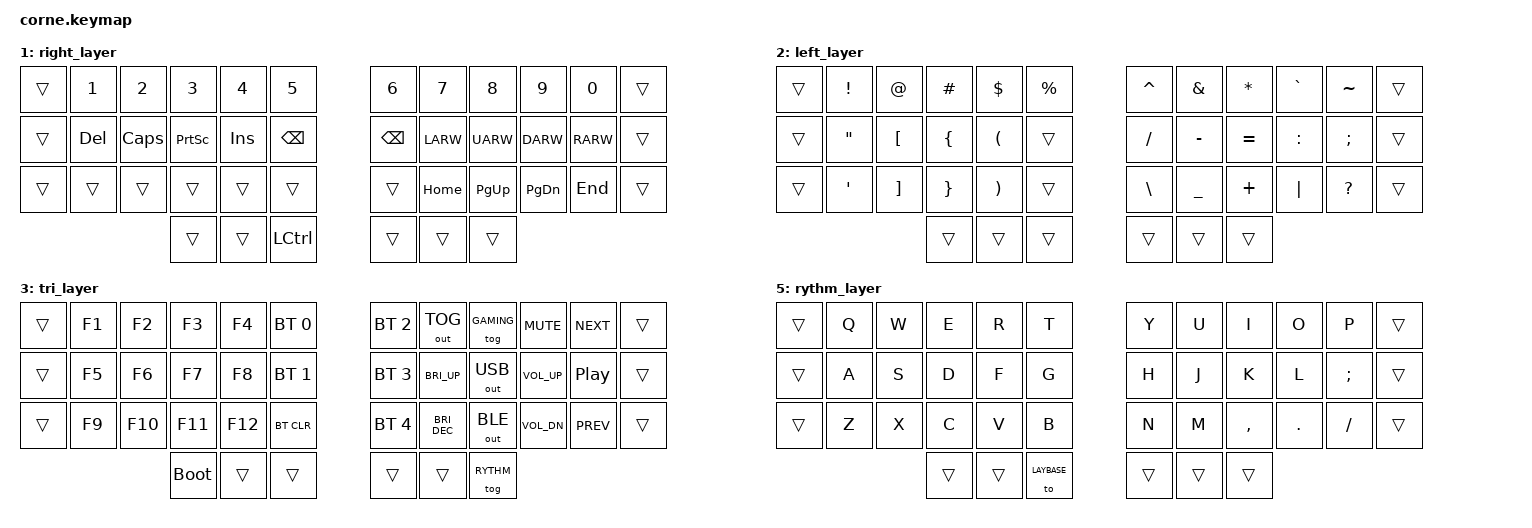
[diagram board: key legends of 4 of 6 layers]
// Copyright (c) 2022 The ZMK Contributors
// SPDX-License-Identifier: MIT
// This should be used with US International keyboard layout for those who need diacritics or Ñ

#include <behaviors.dtsi>
#include <dt-bindings/zmk/keys.h>
#include <dt-bindings/zmk/bt.h>
#include <dt-bindings/zmk/outputs.h>

// Home row mods macro
#define WHRML(k2,k3,k4) &ht LALT k2  &ht LGUI k3  &ht LCTRL k4
#define WHRMR(k1,k2,k3) &ht RCTRL k1  &ht RGUI k2  &ht LALT k3

#define LAYBASE 0
#define LAYRIGHT 1
#define LAYLEFT 2
#define LAYBOTH 3
#define GAMING 4
#define RYTHM 5

/ {
    combos {
        compatible = "zmk,combos";

        combo_space_1 {
            timeout-ms = <50>;                // max delay between key presses (tweak if needed)
            key-positions = <20 21>;    // positions of K and L keys in your matrix
            bindings = <&kp SPACE>;           // output: spacebar
        };
    };

    behaviors {
        ht: hold_tap {
            label = "hold_tap";
            compatible = "zmk,behavior-hold-tap";
            #binding-cells = <2>;
            flavor = "tap-preferred";
            tapping-term-ms = <220>;
            quick-tap-ms = <150>;
            global-quick-tap;
            bindings = <&kp>, <&kp>;
        };
    };

    conditional_layers {
        compatible = "zmk,conditional-layers";
        tri_layer {
            if-layers = <LAYRIGHT LAYLEFT>;
            then-layer = <LAYBOTH>;
        };
    };

    keymap {
        compatible = "zmk,keymap";
        default_layer {
            bindings = <
            &trans   &kp Q   &kp W   &kp E   &kp R   &kp T              &kp Y   &kp U   &kp I   &kp O     &ht RSHIFT P     &trans
            &trans   &kp A   WHRML(S,     D,    F)  &kp G        &kp H  WHRMR(J,     K,      L)   &kp BSPC   &trans
            &trans   &kp Z   &kp X   &kp C   &kp V   &kp B               &kp N   &kp M   &kp COMMA  &kp DOT  &kp ENTER     &trans


              &kp LSHIFT    &lt LAYLEFT ESC &ht LSHIFT SPACE      &ht RSHIFT SPACE    &lt LAYRIGHT TAB  &kp LALT
            >;
        };



        right_layer {
            bindings = <
            &trans   &kp N1    &kp N2     &kp N3     &kp N4    &kp N5          &kp N6     &kp N7     &kp N8     &kp N9     &kp N0    &trans
            &trans   &kp DEL   &kp CAPS   &kp PSCRN  &kp INS   &kp BSPC        &kp BSPC     &kp LARW   &kp UARW   &kp DARW   &kp RARW  &trans
            &trans   &trans    &trans     &trans     &trans    &trans          &trans     &kp HOME   &kp PG_UP  &kp PG_DN  &kp END   &trans
                                    &trans           &trans     &kp LCTRL             &trans     &trans     &trans
            >;
        };

        left_layer {
            bindings = <
        //╭──────────┬──────────┬──────────┬──────────┬──────────╮   ╭──────────┬──────────┬──────────┬──────────┬──────────╮
        //│  !       │  @       │  #       │  $       │  %       │   │  ^       │  &       │  *       │  `       │  ~       │
 &trans  &kp EXCL   &kp AT     &kp HASH   &kp DLLR   &kp PRCNT      &kp CARET  &kp AMPS   &kp ASTRK  &kp GRAVE   &kp TILDE  &trans
        //├──────────┼──────────┼──────────┼──────────┼──────────┤   ├──────────┼──────────┼──────────┼──────────┼──────────┤
        //│  "       │  [       │  {       │  (       │          │   │   /      │  -       │  =       │     :    │  ;       │
 &trans  &kp DQT  &kp LBKT   &kp LBRC   &kp LPAR   &trans         &kp FSLH   &kp MINUS  &kp EQUAL  &kp COLON   &kp SEMI     &trans
        //├──────────┼──────────┼──────────┼──────────┼──────────┤   ├──────────┼──────────┼──────────┼──────────┼──────────┤
        //│  '       │  ]       │  }       │  )       │          │   │    \     │  _       │  +       │  │       │   ?      │
 &trans  &kp SQT     &kp RBKT   &kp RBRC   &kp RPAR   &trans         &kp BSLH   &kp UNDER  &kp PLUS   &kp PIPE  &kp QMARK   &trans
        //╰──────────┴──────────┼──────────┼──────────┼──────────┤   ├──────────┼──────────┼──────────┼──────────┴──────────╯
        //                      |          |          |          |   |          |          |          |
                                   &trans    &trans     &trans          &trans     &trans    &trans  
        //                      ╰──────────┴──────────┴──────────╯   ╰──────────┴──────────┴──────────╯
            >;
        };

        tri_layer {
            bindings = <
&trans   &kp F1     &kp F2     &kp F3     &kp F4     &bt BT_SEL 0     &bt BT_SEL 2  &out OUT_TOG  &tog GAMING  &kp C_MUTE  &kp C_NEXT    &trans
&trans   &kp F5     &kp F6     &kp F7     &kp F8     &bt BT_SEL 1     &bt BT_SEL 3  &kp C_BRI_UP  &out OUT_USB   &kp C_VOL_UP  &kp C_PP    &trans
&trans   &kp F9     &kp F10    &kp F11    &kp F12     &bt BT_CLR      &bt BT_SEL 4  &kp C_BRI_DEC &out OUT_BLE  &kp C_VOL_DN &kp C_PREV  &trans
                                       &bootloader     &trans     &trans         &trans     &trans   &tog RYTHM
            >;
        };

        gaming_layer {
            bindings = <
            &trans   &kp ESC   &kp N1   &kp N2   &kp N3   &kp N4        &kp Y   &kp U   &kp I   &kp O   &kp P          &trans
            &trans   &kp LSHIFT  &kp A   &kp W  &kp D  &kp R        &kp H  WHRMR(J,     K,      L)  &to LAYBASE         &trans
            &trans   &kp LCTRL   &kp Q   &kp S   &kp E   &kp F        &kp N   &kp M   &kp COMMA  &kp DOT  &tog GAMING      &trans


              &kp LCTRL     &kp SPACE  &lt LAYLEFT ESC                              &kp SPACE    &lt LAYRIGHT TAB  &kp LALT
            >;
        };

        rythm_layer {
            bindings = <
            &trans   &kp Q   &kp W   &kp E   &kp R   &kp T        &kp Y   &kp U   &kp I      &kp O     &kp P       &trans
            &trans   &kp A   &kp S   &kp D   &kp F   &kp G        &kp H   &kp J   &kp K      &kp L     &kp SEMI    &trans
            &trans   &kp Z   &kp X   &kp C   &kp V   &kp B        &kp N   &kp M   &kp COMMA  &kp DOT   &kp FSLH    &trans

                               &trans  &trans  &to LAYBASE       &trans  &trans  &trans
            >;
        };
    };
};
